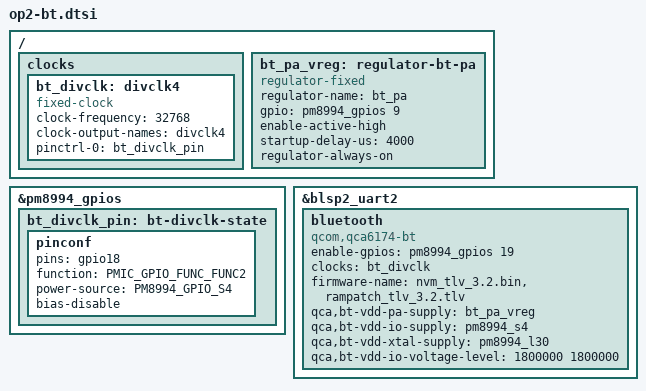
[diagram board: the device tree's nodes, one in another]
// SPDX-License-Identifier: GPL-2.0
#include <dt-bindings/pinctrl/qcom,pmic-gpio.h>
/*
 * OnePlus 2 (DTS_DEFINES=OP2_BT): Bluetooth of the QCA6174 combo (ROME).
 * From the OnePlus kernel (msm8994-mtp.dtsi:18-26, 965-967; board 14049
 * includes it): BT_EN = PM8994 GPIO 19, UART = BLSP2 UART2 (0xf995e000,
 * pins 45-48), vdd-io PM8994 S4 1.8 V (always on), xtal PM8994 L30 1.8 V.
 * Mainline hci_qca "qcom,qca6174-bt" (ROME branch, hci_qca.c:2530 default):
 * needs `enable-gpios` + a 32768 Hz clock (devm_clk_get_optional_enabled_
 * with_rate, SUSCLK_RATE_32KHZ) — the 32k comes from PM8994 gpio18 func2
 * (divclk4), as on msm8994-msft-lumia-octagon.dtsi:50-59,478-486 in
 * mainline. Firmware via DT `firmware-name` → qca/<nome> (btqca.c:784,870):
 * the stock OxygenOS names map 1:1.
 */

/ {
	clocks {
		bt_divclk: divclk4 {
			compatible = "fixed-clock";
			#clock-cells = <0>;
			clock-frequency = <32768>;
			clock-output-names = "divclk4";
			pinctrl-names = "default";
			pinctrl-0 = <&bt_divclk_pin>;
		};
	};
};

&pm8994_gpios {
	bt_divclk_pin: bt-divclk-state {
		pinconf {
			pins = "gpio18";
			function = PMIC_GPIO_FUNC_FUNC2;
			power-source = <PM8994_GPIO_S4>;
			bias-disable;
		};
	};
};

&blsp2_uart2 {
	status = "okay";
	/* as the I2C buses: no BAM DMA for now */
	/delete-property/ dmas;
	/delete-property/ dma-names;

	bluetooth {
		compatible = "qcom,qca6174-bt";
		enable-gpios = <&pm8994_gpios 19 GPIO_ACTIVE_HIGH>;
		clocks = <&bt_divclk>;
		/* loads qca/nvm_tlv_3.2.bin + qca/rampatch_tlv_3.2.tlv
		 * (stock files from system/etc/firmware, p42) */
		firmware-name = "nvm_tlv_3.2.bin", "rampatch_tlv_3.2.tlv";
		/* op2: QCA supplies from CAF msm8994-mtp.dtsi:18-26 */
		qca,bt-vdd-pa-supply = <&bt_pa_vreg>;
		qca,bt-vdd-io-supply = <&pm8994_s4>;
		qca,bt-vdd-xtal-supply = <&pm8994_l30>;
		qca,bt-vdd-io-voltage-level = <1800000 1800000>;
	};
};

/*
 * BT power amplifier supply (OnePlus msm8994-regulator.dtsi:976-982 bt_vreg:
 * regulator-fixed on PM8994 GPIO 9, active high, 4 ms start-up). hci_qca does
 * not handle supplies for ROME, so keep it on.
 */
/ {
	bt_pa_vreg: regulator-bt-pa {
		compatible = "regulator-fixed";
		regulator-name = "bt_pa";
		gpio = <&pm8994_gpios 9 GPIO_ACTIVE_HIGH>;
		enable-active-high;
		startup-delay-us = <4000>;
		regulator-always-on;
	};
};
